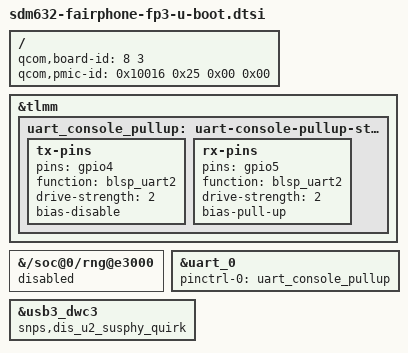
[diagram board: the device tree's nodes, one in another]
// SPDX-License-Identifier: GPL-2.0

/ {
	/*
	 * Match the Fairphone 3 entry of the stock LK so it selects this DTB
	 * when U-Boot is packed into an Android boot image.
	 */
	qcom,board-id = <8 3>;
	qcom,pmic-id = <0x10016 0x25 0x00 0x00>;
};

&tlmm {
	/* The UART is probed before relocation, its pins must be set up by then */
	bootph-all;

	uart_console_pullup: uart-console-pullup-state {
		bootph-all;

		tx-pins {
			bootph-all;
			pins = "gpio4";
			function = "blsp_uart2";
			drive-strength = <2>;
			bias-disable;
		};

		/* The debug UART pads are usually left unconnected */
		rx-pins {
			bootph-all;
			pins = "gpio5";
			function = "blsp_uart2";
			drive-strength = <2>;
			bias-pull-up;
		};
	};
};

/* The PRNG is owned by the secure world, any access from U-Boot traps */
&{/soc@0/rng@e3000} {
	status = "disabled";
};

&uart_0 {
	pinctrl-0 = <&uart_console_pullup>;
	pinctrl-names = "default";
};

/*
 * With the USB2 PHY allowed to suspend, the controller keeps it suspended
 * after U-Boot stops USB, and the PHY PLL no longer locks when the next USB
 * function powers it on.
 */
&usb3_dwc3 {
	snps,dis_u2_susphy_quirk;
};
